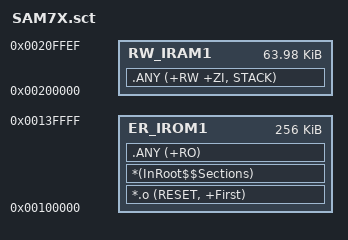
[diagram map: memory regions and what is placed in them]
; *************************************************************
; *** Scatter-Loading Description File generated by uVision ***
; *************************************************************

LR_IROM1 0x00100000 0x00040000        {    ; load region
  ER_IROM1 0x00100000 0x00040000  {  ; load address = execution address
   *.o (RESET, +First)
   *(InRoot$$Sections)
   .ANY (+RO)
  }
  RW_IRAM1 0x00200000 0x0000FFF0  {  ; RW data
   .ANY (+RW +ZI, STACK)
  }

}

